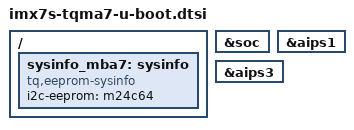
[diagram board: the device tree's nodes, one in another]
// SPDX-License-Identifier: GPL-2.0-or-later OR MIT
/*
 * Device Tree Source for TQ-Systems TQMa7S module.
 *
 * Copyright (C) 2024-2026 TQ-Systems GmbH <u-boot@ew.tq-group.com>,
 * D-82229 Seefeld, Germany
 * Author: Steffen Doster
 */

#include "imx7s-u-boot.dtsi"

/ {
	sysinfo_mba7: sysinfo {
		compatible = "tq,eeprom-sysinfo";
		i2c-eeprom = <&m24c64>;
	};
};

&soc {
	bootph-pre-ram;
};

&aips1 {
	bootph-pre-ram;
};

&aips3 {
	bootph-pre-ram;
};
